# RZT2H register map
Vendor: Renesas Electronics Corporation; Series: RZT; File version: 1.00.00
CPU: other r0p0, little endian, MPU, no FPU, VTOR, 4 interrupt priority bits, 624 interrupts
Registers are 32-bit, read-write, reset 0x0 unless marked. A register's access mark holds for its fields unless they carry their own. Offsets are from the block's base; [hi:lo] are bit positions; {n}, {i} and the like mark numbered series; 'fields as' and 'values as' point back to an identical list.

## TFU0 — Trigonometric Function Unit 0
Base 0x90010000
Same registers: TFU1 0x90110000
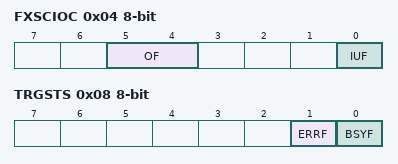
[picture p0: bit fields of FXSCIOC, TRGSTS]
0x04 FXSCIOC 8-bit — Fixed-point Sine Cosine Input/Output Setting Register
  [5:4] OF — Output format setting
    0=Q1.31; 1=Q2.30; 2=Q3.29; 3=Setting prohibited
  [0] IUF — Input unit and format setting
    0=unit, format = turn, Q1.31; 1=unit, format = radian, Q3.29
0x05 FXATIOC 8-bit — Fixed-point Arctangent hypot_k Input/Output Setting Register
  [4] OUF — Output unit and format setting
    0=unit, format = turn, Q1.31; 1=unit, format = radian, Q3.29
0x08 TRGSTS 8-bit — Trigonometric Status Register
  [1] ERRF — Input error flag
    0=No input error occurred; 1=Input error occurred
  [0] BSYF — Calculation in progress flag
    0=No calculating; 1=Calculating
0x10 FPSCDT0 — Floating-point Sine Cosine Data Register 0
0x14 FPSCDT1 — Floating-point Sine Cosine Data Register 1
0x18 FPATDT0 — Floating-point Arctangent hypot_k Data Register 0
0x1C FPATDT1 — Floating-point Arctangent hypot_k Data Register 1
0x20 FXSCDT0 — Fixed-point Sine Cosine Data Register
  [31:0] FXSCDT0 — Fixed-point Sine Cosine Data Register 0
0x24 FXSCDT1 — Fixed-point Sine Cosine Data Register 1
0x28 FXATDT0 — Fixed-point Arctangent hypot_k Data Register 0
0x2C FXATDT1 — Fixed-point Arctangent hypot_k Data Register 1
0x30 DTSR0 — Data Save Restore Register 0
0x34 DTSR1 — Data Save Restore Register 1

## POEG0 — GPT Port Output Enable 0
Base 0x90019000
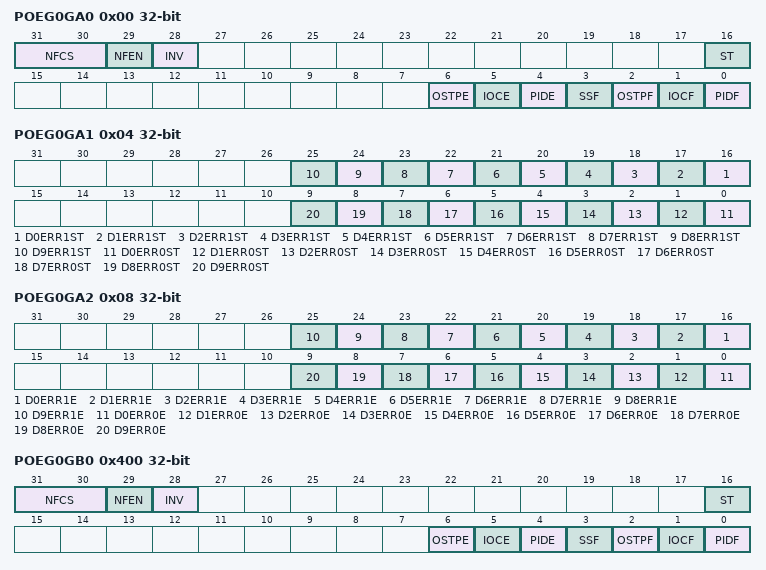
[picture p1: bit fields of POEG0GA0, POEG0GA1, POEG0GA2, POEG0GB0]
0x00 POEG0GA0 — POEG0 Group A Setting Register 0
  [31:30] NFCS — Noise filter Clock Select
    0=Samples the input level of GTETRGn pin three times per PCLKH clock; 1=Samples the input level of GTETRGn pin three times per PCLKH/8 clock; 2=Samples the input level of GTETRGn pin three times per PCLKH/32 clock; 3=Samples the input level of GTETRGn pin three times per PCLKH/128 clock
  [29] NFEN — Noise filter Enable
    0=Digital noise filter on the GTETRGn pin is disabled; 1=Digital noise filter on the GTETRGn pin is enabled
  [28] INV — GTETRGn Input Inverting
    0=Input on the GTETRGn pin is not inverted; 1=Input on the GTETRGn pin is inverted
  [16] ST ro — GTETRGn Input Status Flag
    0=GTETRGn input after filtering was 0; 1=GTETRGn input after filtering was 1
  [6] OSTPE — Enable Stopping Output on Stopping of Oscillation
    0=Detection of stopping of oscillation is disabled; 1=Detection of stopping of oscillation is enabled
  [5] IOCE — GPT Output Stop Request Enable
    0=Detection of stopping of output from the GPT is disabled; 1=Detection of stopping of output from the GPT is enabled
  [4] PIDE — Port Input Detection Enable
    0=Detection of input levels on the corresponding GTETRGn pin is disabled; 1=Detection of input levels on the corresponding GTETRGn pin is enabled
  [3] SSF — Software Stop Flag
    0=Software has not stopped output; 1=Software has stopped output
  [2] OSTPF — Oscillation Stop Detection Flag
    0=Stopping of oscillation was not detected; 1=Stopping of oscillation was detected
  [1] IOCF — GPT Output Stop Request Detection Flag
    0=Stopping of GPT output was not detected; 1=Stopping of GPT output was detected
  [0] PIDF — Port Input Detection Flag
    0=The selected input level was not detected on the GTETRGn pin; 1=The selected input level was detected on the GTETRGn pin
0x04 POEG0GA1 ro — POEG0 Group A Setting Register 1
  [n+16] D{n}ERR1ST (n=0..9)
    0=Indicates that DSMIF{n} error 1 has not been generated; 1=Indicates that DSMIF{n} error 1 has been generated
  [n] D{n}ERR0ST (n=0..9)
    0=Indicates that DSMIF{n} error 0 has not been generated; 1=Indicates that DSMIF{n} error 0 has been generated
0x08 POEG0GA2 — POEG0 Group A Setting Register 2
  [all] fields
    0=Disabled; 1=Enabled
  [n+16] D{n}ERR1E (n=0..9)
  [n] D{n}ERR0E (n=0..9)
0x400 POEG0GB0 — POEG0 Group B Setting Register 0
  fields as POEG0GA0
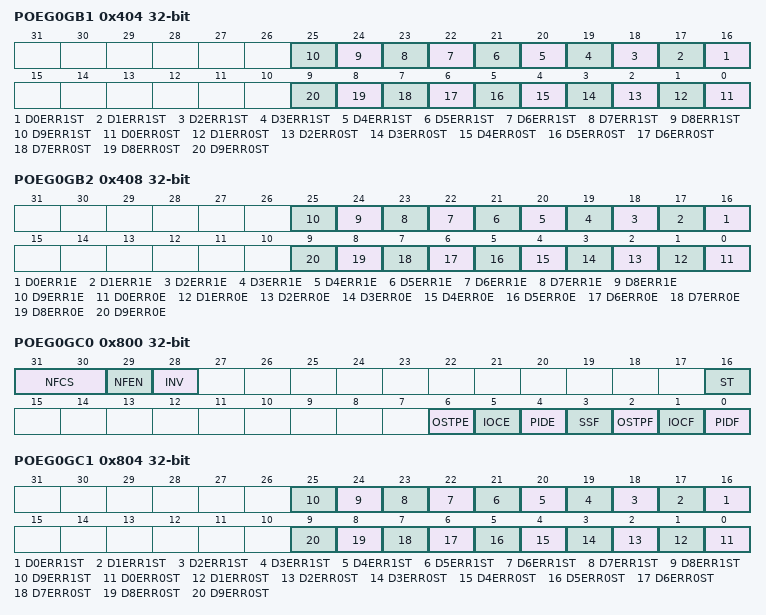
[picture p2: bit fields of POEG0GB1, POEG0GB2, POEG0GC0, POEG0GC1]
0x404 POEG0GB1 ro — POEG0 Group B Setting Register 1
  fields as POEG0GA1
0x408 POEG0GB2 — POEG0 Group B Setting Register 2
  fields as POEG0GA2
0x800 POEG0GC0 — POEG0 Group C Setting Register 0
  fields as POEG0GA0
0x804 POEG0GC1 ro — POEG0 Group C Setting Register 1
  fields as POEG0GA1
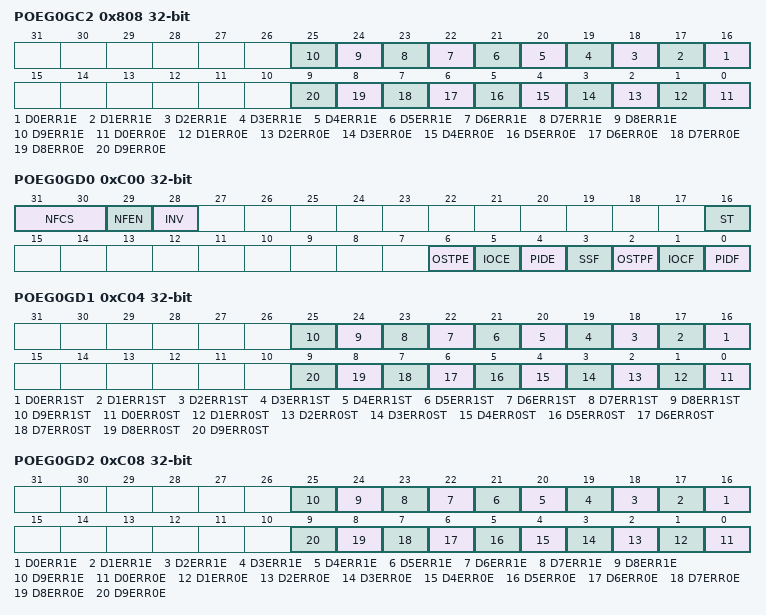
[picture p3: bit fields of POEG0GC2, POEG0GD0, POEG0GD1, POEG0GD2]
0x808 POEG0GC2 — POEG0 Group C Setting Register 2
  fields as POEG0GA2
0xC00 POEG0GD0 — POEG0 Group D Setting Register 0
  fields as POEG0GA0
0xC04 POEG0GD1 ro — POEG0 Group D Setting Register 1
  fields as POEG0GA1
0xC08 POEG0GD2 — POEG0 Group D Setting Register 2
  fields as POEG0GA2
